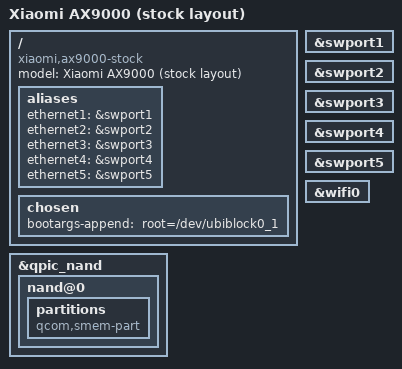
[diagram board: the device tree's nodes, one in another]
// SPDX-License-Identifier: GPL-2.0-or-later OR MIT

#include "ipq8072-ax9000.dts"

/ {
	model = "Xiaomi AX9000 (stock layout)";
	compatible = "xiaomi,ax9000-stock", "qcom,ipq8074";

	aliases {
		/* Aliases as required by u-boot to patch MAC addresses */
		ethernet1 = &swport1;
		ethernet2 = &swport2;
		ethernet3 = &swport3;
		ethernet4 = &swport4;
		ethernet5 = &swport5;
	};

	chosen {
		bootargs-append = " root=/dev/ubiblock0_1";
	};
};

&qpic_nand {
	/delete-node/ partitions;

	nand@0 {
		/delete-node/ partitions;

		partitions {
			compatible = "qcom,smem-part";
		};
	};
};

&swport1 {
	/delete-property/ nvmem-cells;
	/delete-property/ nvmem-cell-names;
};

&swport2 {
	/delete-property/ nvmem-cells;
	/delete-property/ nvmem-cell-names;
};

&swport3 {
	/delete-property/ nvmem-cells;
	/delete-property/ nvmem-cell-names;
};

&swport4 {
	/delete-property/ nvmem-cells;
	/delete-property/ nvmem-cell-names;
};

&swport5 {
	/delete-property/ nvmem-cells;
	/delete-property/ nvmem-cell-names;
};

&wifi0 {
	/delete-property/ nvmem-cells;
	/delete-property/ nvmem-cell-names;
};
